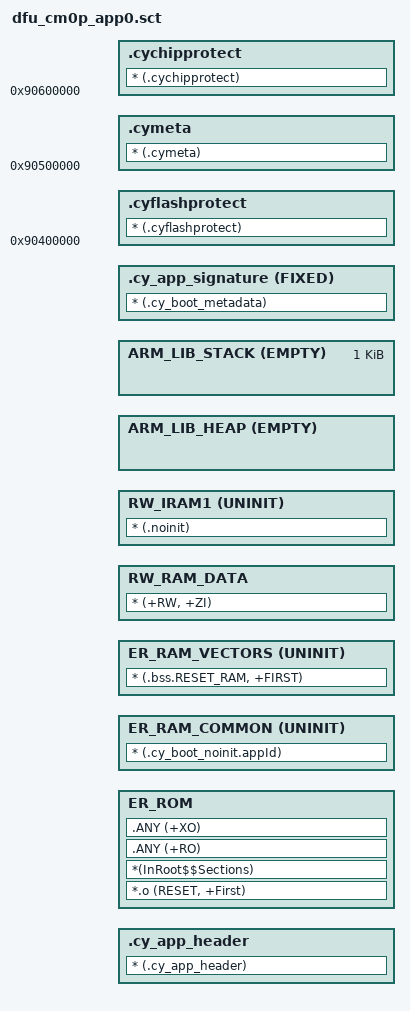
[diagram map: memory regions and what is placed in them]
#! armclang -E --target=arm-arm-none-eabi -x c -mcpu=cortex-m4
; The first line specifies a preprocessor command that the linker invokes
; to pass a scatter file through a C preprocessor.

;***************************************************************************//**
;* \file dfu_cm0p_app0.sct
;* \version 4.10
;*
;* The linker file for the the ARM compiler.
;* Used for the DFU SDK application 0 firmware project.
;*
;* \note
;* This linker file is generic and handles common use cases. Your project may not
;* use each section defined in the linker file and then you may see warnings
;* during the build process: L6314W (no section matches the pattern) and/or
;* L6329W (the pattern only matches removed unused sections).
;* You can suppress a warning by passing the "--diag_suppress=L6314W,L6329W"
;* option to the linker. Simply comment out or remove the relevant code in the
;* linker file.
;*
;*******************************************************************************
;* \copyright
;* Copyright 2016-2019, Cypress Semiconductor Corporation.  All rights reserved.
;* You may use this file only in accordance with the license, terms, conditions,
;* disclaimers, and limitations in the end user license agreement accompanying
;* the software package with which this file was provided.
;******************************************************************************/

;* DFU SDK specific: includes defines common across all the applications
#include "dfu_common.h"

;* DFU SDK specific: defines the memory regions
;* Make sure the correct app number is entered here

; RAM
#define RAM_START               CY_APP0_RAM_ADDR
#define RAM_SIZE                CY_APP0_RAM_LENGTH

; Flash
#define FLASH_START             CY_APP0_FLASH_ADDR
#define FLASH_SIZE              CY_APP0_FLASH_LENGTH

#define STACK_SIZE              0x00000400


LR_ROM FLASH_START FLASH_SIZE
{
    .cy_app_header +0
    {
        * (.cy_app_header)
    }

    ER_ROM FLASH_START FLASH_SIZE
    {
        *.o (RESET, +First)
        *(InRoot$$Sections)
        .ANY (+RO)
        .ANY (+XO)
    }

    ER_RAM_COMMON CY_APP_RAM_COMMON_ADDR UNINIT
    {
        * (.cy_boot_noinit.appId)
    }

    ER_RAM_VECTORS RAM_START UNINIT
    {
        * (.bss.RESET_RAM, +FIRST)
    }

    RW_RAM_DATA +0
    {
        * (+RW, +ZI)
    }

    ; Place variables in the section that should not be initialized during the
    ; device startup.
    RW_IRAM1 +0 UNINIT
    {
        * (.noinit)
    }

    ; Application heap area (HEAP)
    ARM_LIB_HEAP  +0 EMPTY ((RAM_START+RAM_SIZE)-AlignExpr(ImageLimit(RW_IRAM1), 8)-STACK_SIZE)
    {
    }

    ; Stack region growing down
    ARM_LIB_STACK (RAM_START+RAM_SIZE) EMPTY -STACK_SIZE
    {
    }

    ; Used for the digital signature of the Cypress Standard Application and the
    ; DFU SDK application. The size of the section depends on the required
    ; data size.
    .cy_app_signature (FLASH_START + FLASH_SIZE - CY_BOOT_SIGNATURE_SIZE) FIXED
    {
        * (.cy_app_signature)
    }
}

; App0 uses it to initialize DFU SDK metadata, in dfu_user.c file
LR_CY_BOOT_METADATA CY_BOOT_META_FLASH_ADDR CY_BOOT_META_FLASH_LENGTH
{
    .cy_boot_metadata + 0
    {
        * (.cy_boot_metadata)
    }
}

; The section is used for additional metadata (silicon revision, Silicon/JTAG ID, etc.) storage.
CYFLASHPROTECT 0x90400000
{
    .cyflashprotect +0 { * (.cyflashprotect) }
}

CYMETA 0x90500000
{
    .cymeta +0 { * (.cymeta) }
}

CYCHIPPROTECT 0x90600000
{
    .cychipprotect +0 { * (.cychipprotect) }
}


/* [] END OF FILE */
